# ATSAM4LC8C device description
Architecture: CORTEX-M4; Family: SAM4; Series: SAM4L
Registers are 32-bit, read-write, reset 0x0 unless marked. A register's access mark holds for its fields unless they carry their own. Offsets are from the block's base; [hi:lo] are bit positions; {n}, {i} and the like mark numbered series; 'fields as' and 'values as' point back to an identical list.

## DACC — DAC Controller
Instances: DACC 0x4003C000
0x00 CR wo — Control Register
  [0] SWRST — Software Reset
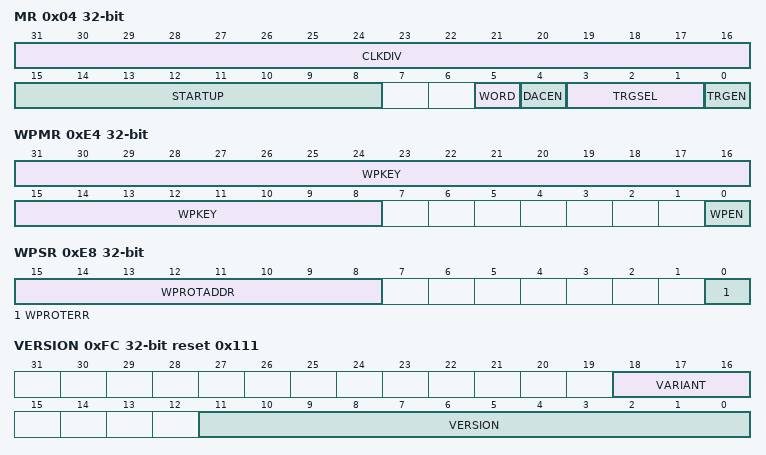
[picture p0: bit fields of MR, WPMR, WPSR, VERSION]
0x04 MR — Mode Register
  [31:16] CLKDIV — Clock Divider for Internal Trigger
  [15:8] STARTUP — Startup Time Selection
  [5] WORD — Word Transfer
  [4] DACEN — DAC Enable
  [3:1] TRGSEL — Trigger Selection
  [0] TRGEN — Trigger Enable
0x08 CDR wo — Conversion Data Register
  [31:0] DATA — Data to Convert
0x0C IER wo (atomic set of IMR) — Interrupt Enable Register
  [0] TXRDY — Transmit Ready Interrupt Enable
0x10 IDR wo reset not defined (atomic clear of IMR) — Interrupt Disable Register
  [0] TXRDY — Transmit Ready Interrupt Disable
0x14 IMR ro — Interrupt Mask Register
  [0] TXRDY — Transmit Ready Interrupt Mask
0x18 ISR ro — Interrupt Status Register
  [0] TXRDY — Transmit Ready Interrupt Status
0xE4 WPMR — Write Protect Mode Register
  [31:8] WPKEY — Write Protect Key
  [0] WPEN — Write Protect Enable
0xE8 WPSR ro — Write Protect Status Register
  [15:8] WPROTADDR — Write Protection Error Address
  [0] WPROTERR — Write Protection Error
0xFC VERSION ro reset 0x111
  [18:16] VARIANT — Variant Number
  [11:0] VERSION — Version Number

## EIC — External Interrupt Controller
Instances: EIC 0x400F1000
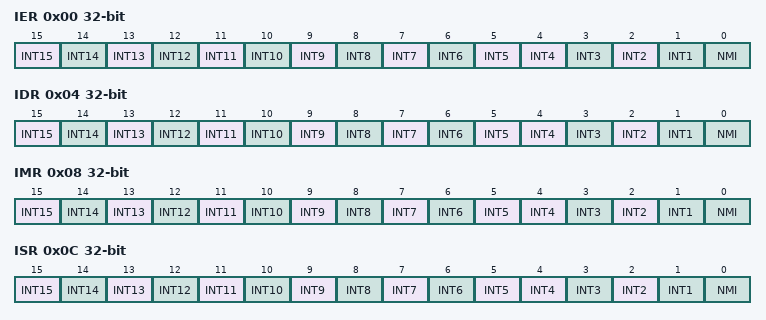
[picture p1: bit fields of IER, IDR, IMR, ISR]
0x00 IER wo (atomic set of IMR) — Interrupt Enable Register
  [n] INT{n} (n=5..15) — External Interrupt {n}
  [n] INT{n} (n=1..4) — External Interrupt {n}
    0=No effect; 1=Enable Interrupt
  [0] NMI — External Non Maskable CPU interrupt
0x04 IDR wo (atomic clear of IMR) — Interrupt Disable Register
  [n] INT{n} (n=5..15) — External Interrupt {n}
  [n] INT{n} (n=1..4) — External Interrupt {n}
    0=No effect; 1=Disable Interrupt
  [0] NMI — External Non Maskable CPU interrupt
0x08 IMR ro — Interrupt Mask Register
  [n] INT{n} (n=5..15) — External Interrupt {n}
  [n] INT{n} (n=1..4) — External Interrupt {n}
    0=Interrupt is disabled; 1=Interrupt is enabled
  [0] NMI — External Non Maskable CPU interrupt
0x0C ISR ro — Interrupt Status Register
  [n] INT{n} (n=5..15) — External Interrupt {n}
  [n] INT{n} (n=1..4) — External Interrupt {n}
    0=An interrupt event has not occurred; 1=An interrupt event has occurred
  [0] NMI — External Non Maskable CPU interrupt
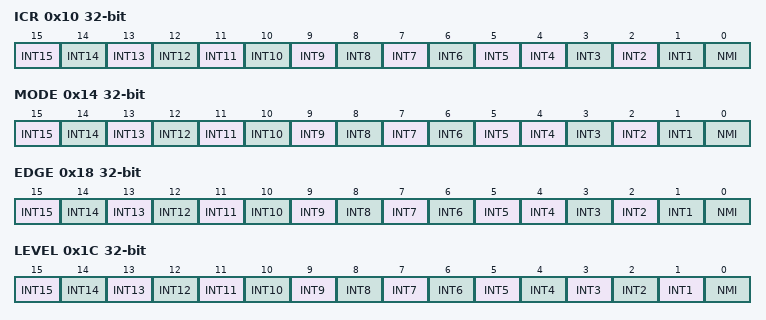
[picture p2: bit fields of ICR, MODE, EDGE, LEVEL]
0x10 ICR wo (atomic clear of ISR) — Interrupt Clear Register
  [n] INT{n} (n=5..15) — External Interrupt {n}
  [n] INT{n} (n=1..4) — External Interrupt {n}
    0=No effect; 1=Clear Interrupt
  [0] NMI — External Non Maskable CPU interrupt
0x14 MODE
  [n] INT{n} (n=5..15) — External Interrupt {n}
  [n] INT{n} (n=1..4) — External Interrupt {n}
    0=Edge triggered interrupt; 1=Level triggered interrupt
  [0] NMI — External Non Maskable CPU interrupt
0x18 EDGE
  [n] INT{n} (n=5..15) — External Interrupt {n}
  [n] INT{n} (n=1..4) — External Interrupt {n}
    0=Triggers on falling edge; 1=Triggers on rising edge
  [0] NMI — External Non Maskable CPU interrupt
0x1C LEVEL
  [n] INT{n} (n=1..15) — External Interrupt {n}
  [0] NMI — External Non Maskable CPU interrupt
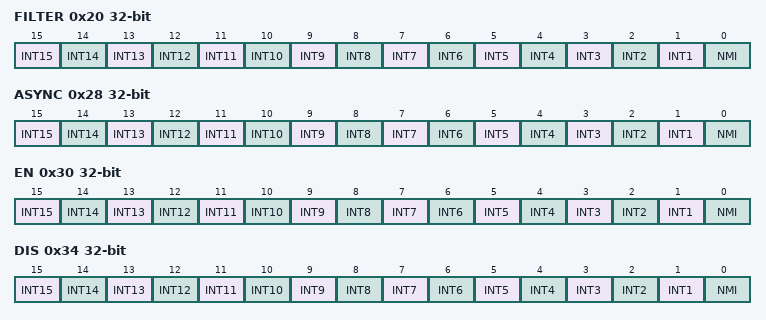
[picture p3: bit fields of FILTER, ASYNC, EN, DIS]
0x20 FILTER
  fields as LEVEL
0x28 ASYNC — Asynchronous Register
  fields as LEVEL
0x30 EN wo (atomic set of CTRL) — Enable Register
  fields as LEVEL
0x34 DIS wo (atomic clear of CTRL) — Disable Register
  fields as LEVEL
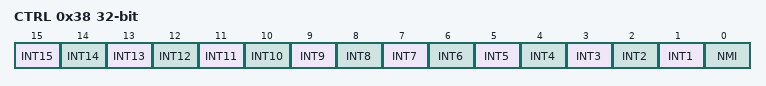
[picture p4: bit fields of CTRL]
0x38 CTRL ro — Control Register
  fields as LEVEL
0x3FC VERSION ro reset 0x302
  [11:0] VERSION — Version bits

## FLASHCALW — Flash Controller
Instances: HFLASHC 0x400A0000
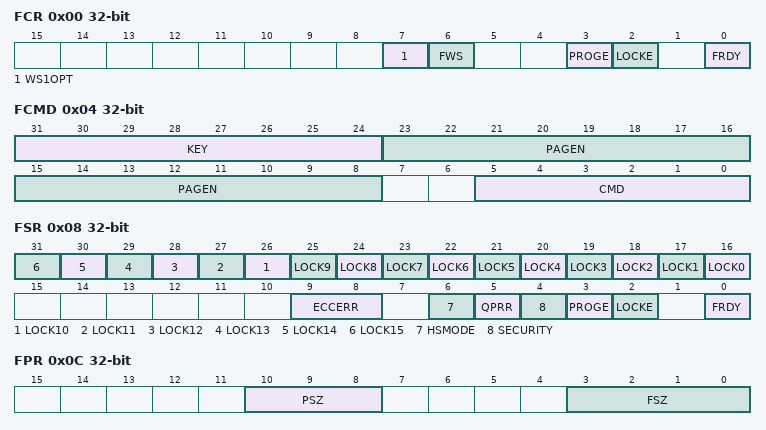
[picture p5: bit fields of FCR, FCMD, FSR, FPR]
0x00 FCR — Flash Controller Control Register
  [7] WS1OPT — Wait State 1 Optimization
  [6] FWS — Flash Wait State
    0=The flash is read with 0 wait states; 1=The flash is read with 1 wait states
  [3] PROGE — Programming Error Interrupt Enable
    0=Programming Error does not generate an interrupt; 1=Programming Error generates an interrupt
  [2] LOCKE — Lock Error Interrupt Enable
    0=Lock Error does not generate an interrupt; 1=Lock Error generates an interrupt
  [0] FRDY — Flash Ready Interrupt Enable
    0=Flash Ready does not generate an interrupt; 1=Flash Ready generates an interrupt
0x04 FCMD — Flash Controller Command Register
  [31:24] KEY — Write protection key
    165=KEY
  [23:8] PAGEN — Page number
  [5:0] CMD — Command
    0=NOP (No Operation); 1=WP (Write Page); 2=EP (Erase Page); 3=CPB (Clear Page Buffer); 4=LP (Lock Region containing page); 5=UP (Unlock Region containing page); 6=EA (Erase All, including secuity and fuse bits); 7=WGPB (Write General-Purpose fuse Bit); 8=EGPB (Erase General-Purpose fuse Bit); 9=SSB (Set Security Bit); 10=PGPFB (Program GPFuse Byte); 11=EAGPF (Erase All GP Fuses); 12=QPR (Quick Page Read); 13=WUP (Write User Page); 14=EUP (Erase User Page); 15=QPRUP (Quick Page Read User Page); 16=HSEN (High Speed Mode Enable); 17=HSDIS (High Speed Mode Disable)
0x08 FSR — Flash Controller Status Register
  [n+16] LOCK{n} (n=0..15) — Lock Region {n} Lock Status
  [9:8] ECCERR — ECC Error Status
    0=NOERROR; 1=ONEECCERR (One ECC error detected); 2=TWOECCERR (Two ECC errors detected)
  [6] HSMODE — High Speed Mode
  [5] QPRR — Quick Page Read Result
  [4] SECURITY — Security Bit Status
  [3] PROGE — Programming Error Status
  [2] LOCKE — Lock Error Status
  [0] FRDY — Flash Ready Status
0x0C FPR ro reset not defined — Flash Controller Parameter Register
  [10:8] PSZ — Page Size
  [3:0] FSZ — Flash Size
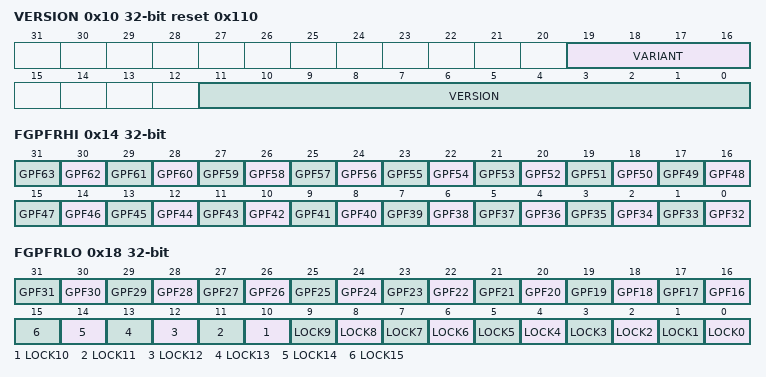
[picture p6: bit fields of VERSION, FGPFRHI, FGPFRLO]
0x10 VERSION ro reset 0x110 — Flash Controller Version Register
  [19:16] VARIANT — Variant Number
  [11:0] VERSION — Version Number
0x14 FGPFRHI reset not defined — Flash Controller General Purpose Fuse Register High
  [n-32] GPF{n} (n=32..63) — General Purpose Fuse {n}
0x18 FGPFRLO reset not defined — Flash Controller General Purpose Fuse Register Low
  [n] GPF{n} (n=16..31) — General Purpose Fuse {n}
  [n] LOCK{n} (n=0..15) — Lock Bit {n}
